# STM32U545xx register map
File version: 1.0
Registers are 32-bit, read-write, reset 0x0 unless marked. A register's access mark holds for its fields unless they carry their own. Offsets are from the block's base; [hi:lo] are bit positions; {n}, {i} and the like mark numbered series; 'fields as' and 'values as' point back to an identical list.

## VREFBUF
Base 0x46007400
Same registers: VREFBUF_S 0x56007400
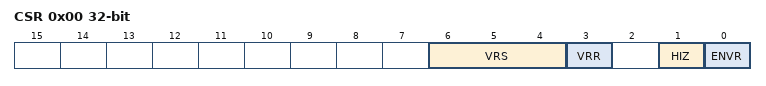
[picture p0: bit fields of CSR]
0x00 CSR — VREFBUF control and status register
  [6:4] VRS — Voltage reference scale
    {v}=SCALE{v} (Voltage reference scale {v} (VREF_OUT{v+1})) (v=0..3)
  [3] VRR — Voltage reference buffer ready
  [1] HIZ — High impedance mode
  [0] ENVR — Voltage reference buffer enable
0x04 CCR — VREFBUF calibration and control register
  [5:0] TRIM — TRIM[5:0] bits (Trimming code)

## EXTI — Asynch Interrupt/Event Controller (EXTI)
Base 0x46022000
Same registers: EXTI_S 0x56022000
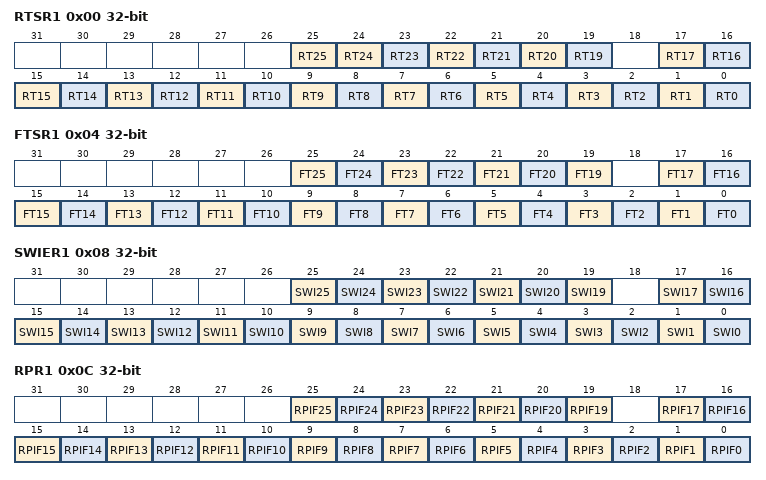
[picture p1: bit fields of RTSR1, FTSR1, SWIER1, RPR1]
0x00 RTSR1 — EXTI Rising Trigger Selection Register 1
  [25] RT25 — Rising trigger configuration for input line 24
  [n] RT{n} (n=19..24) — Rising trigger configuration for input line {n}
  [n] RT{n} (n=0..17) — Rising trigger configuration for input line {n}
0x04 FTSR1 — EXTI Falling Trigger Selection Register 1
  [n] FT{n} (n=19..25) — Falling trigger configuration for input line {n}
  [n] FT{n} (n=0..17) — Falling trigger configuration for input line {n}
0x08 SWIER1 — EXTI Software Interrupt event Register 1
  [n] SWI{n} (n=19..25) — Software Interrupt on line {n}
  [n] SWI{n} (n=0..17) — Software Interrupt on line {n}
0x0C RPR1 — EXTI Rising Pending Register 1
  [n] RPIF{n} (n=19..25) — Rising Pending Interrupt Flag on line {n}
  [n] RPIF{n} (n=0..17) — Rising Pending Interrupt Flag on line {n}
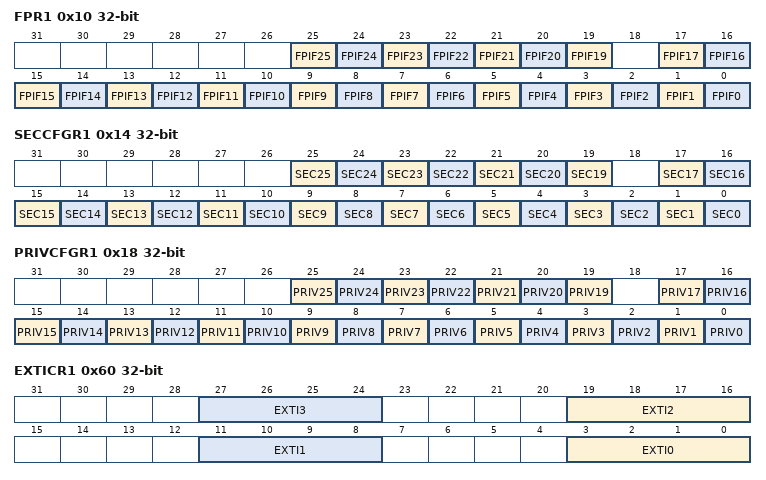
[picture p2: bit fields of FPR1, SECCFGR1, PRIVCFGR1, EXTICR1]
0x10 FPR1 — EXTI Falling Pending Register 1
  [n] FPIF{n} (n=19..25) — Falling Pending Interrupt Flag on line {n}
  [n] FPIF{n} (n=0..17) — Falling Pending Interrupt Flag on line {n}
0x14 SECCFGR1 — EXTI Security Configuration Register 1
  [n] SEC{n} (n=19..25) — Security enable on line {n}
  [n] SEC{n} (n=0..17) — Security enable on line {n}
0x18 PRIVCFGR1 — EXTI Privilege Configuration Register 1
  [n] PRIV{n} (n=19..25) — Privilege enable on line {n}
  [n] PRIV{n} (n=0..17) — Privilege enable on line {n}
0x60 EXTICR1 — EXIT External Interrupt Configuration Register, 0x60 -- 0x6C
  [8n+3:8n] EXTI{n} (n=0..3) — EXTI {n} configuration
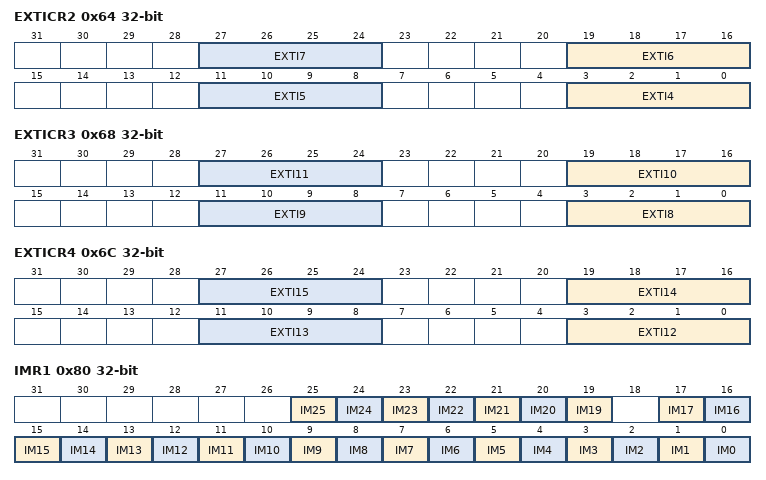
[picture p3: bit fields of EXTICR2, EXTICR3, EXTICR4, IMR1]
0x64 EXTICR2 — EXIT External Interrupt Configuration Register, 0x60 -- 0x6C
  [8n-29:8n-32] EXTI{n} (n=4..7) — EXTI {n} configuration
0x68 EXTICR3 — EXIT External Interrupt Configuration Register, 0x60 -- 0x6C
  [8n-61:8n-64] EXTI{n} (n=8..11) — EXTI {n} configuration
0x6C EXTICR4 — EXIT External Interrupt Configuration Register, 0x60 -- 0x6C
  [8n-93:8n-96] EXTI{n} (n=12..15) — EXTI {n} configuration
0x70 LOCKR — EXTI Lock Register
  [0] LOCK — Global security and privilege configuration registers lock
0x80 IMR1 — EXTI Interrupt Mask Register 1
  [n] IM{n} (n=19..25) — Interrupt Mask on line {n}
  [n] IM{n} (n=0..17) — Interrupt Mask on line {n}
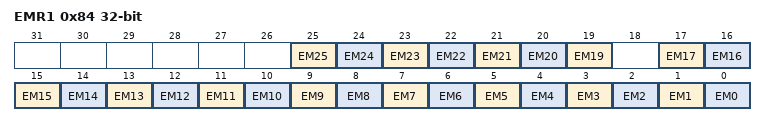
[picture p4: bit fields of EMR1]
0x84 EMR1 — EXTI Event Mask Register 1
  [n] EM{n} (n=19..25) — Event Mask on line {n}
  [n] EM{n} (n=0..17) — Event Mask on line {n}

## GTZC_TZIC2
Base 0x46023400
Same registers: GTZC_TZIC2_S 0x56023400
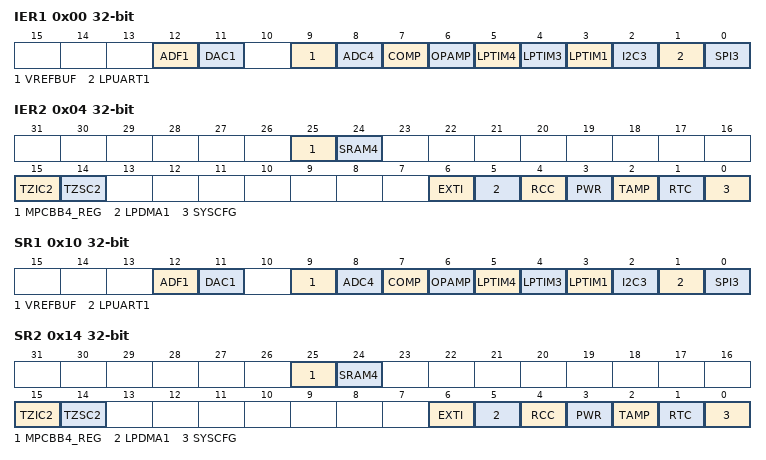
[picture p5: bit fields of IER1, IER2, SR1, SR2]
0x00 IER1 — TZIC interrupt enable register 1
  [12] ADF1, [11] DAC1, [9] VREFBUF, [8] ADC4, [7] COMP, [6] OPAMP, [5] LPTIM4, [4] LPTIM3, [3] LPTIM1, [2] I2C3, [1] LPUART1, [0] SPI3
0x04 IER2 — TZIC interrupt enable register 2
  [25] MPCBB4_REG, [24] SRAM4, [15] TZIC2, [14] TZSC2, [6] EXTI, [5] LPDMA1, [4] RCC, [3] PWR, [2] TAMP, [1] RTC, [0] SYSCFG
0x08 IER3 — TZIC interrupt enable register 3
0x0C IER4 — TZIC interrupt enable register 4
0x10 SR1 — TZIC status register 1
  fields as IER1
0x14 SR2 — TZIC status register 2
  fields as IER2
0x18 SR3 — TZIC status register 3
0x1C SR4 — TZIC status register 4
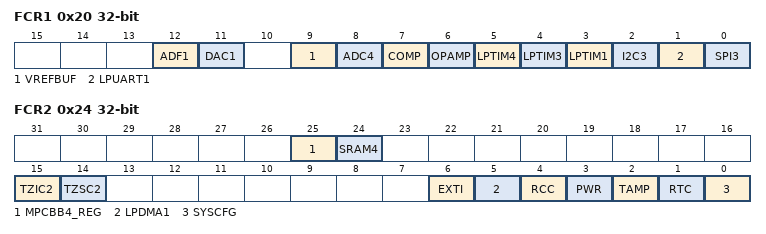
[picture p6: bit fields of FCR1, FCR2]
0x20 FCR1 — TZIC flag clear register 1
  fields as IER1
0x24 FCR2 — TZIC flag clear register 2
  fields as IER2
0x28 FCR3 — TZIC flag clear register 3
0x2C FCR4 — TZIC flag clear register 3

## DBGMCU — Debug MCU
Base 0xE0044000
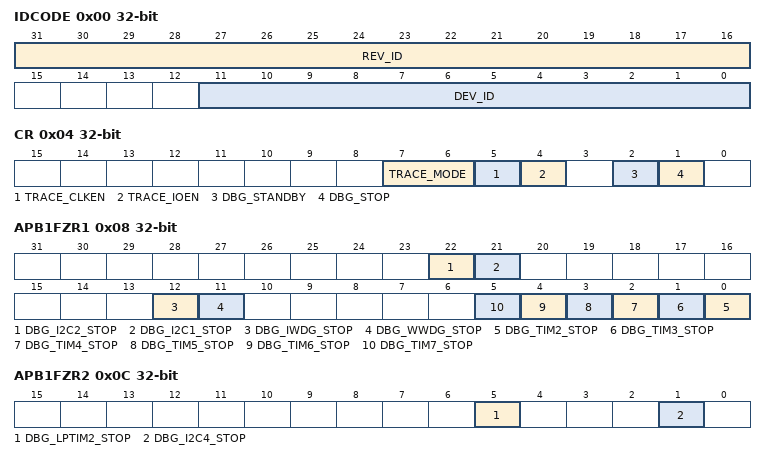
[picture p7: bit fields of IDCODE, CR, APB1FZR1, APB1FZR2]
0x00 IDCODE — MCU device ID code
  [31:16] REV_ID, [11:0] DEV_ID
0x04 CR — Debug MCU configuration register
  [7:6] TRACE_MODE, [5] TRACE_CLKEN, [4] TRACE_IOEN, [2] DBG_STANDBY, [1] DBG_STOP
0x08 APB1FZR1 — Debug MCU APB1 freeze register 1
  [22] DBG_I2C2_STOP, [21] DBG_I2C1_STOP, [12] DBG_IWDG_STOP, [11] DBG_WWDG_STOP, [n-2] DBG_TIM{n}_STOP (n=2..7)
0x0C APB1FZR2 — Debug MCU APB1 freeze register 2
  [5] DBG_LPTIM2_STOP, [1] DBG_I2C4_STOP
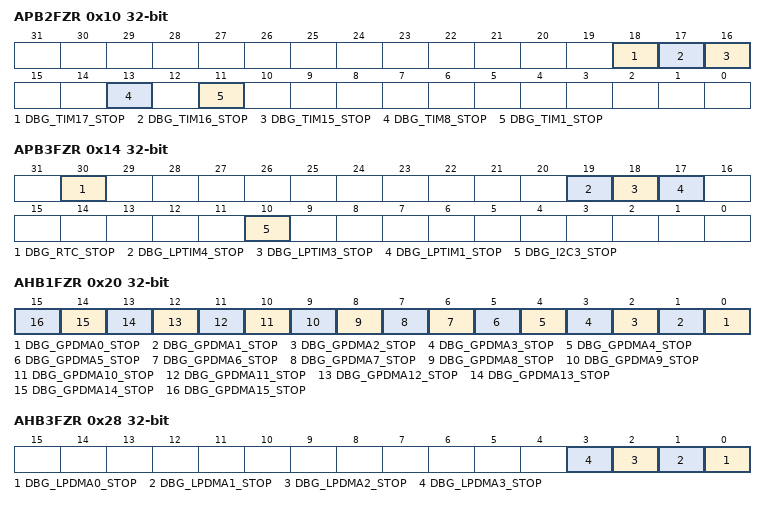
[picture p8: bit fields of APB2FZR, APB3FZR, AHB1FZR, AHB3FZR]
0x10 APB2FZR — Debug MCU APB2 freeze register
  [18] DBG_TIM17_STOP, [17] DBG_TIM16_STOP, [16] DBG_TIM15_STOP, [13] DBG_TIM8_STOP, [11] DBG_TIM1_STOP
0x14 APB3FZR — Debug MCU APB3 freeze register
  [30] DBG_RTC_STOP, [19] DBG_LPTIM4_STOP, [18] DBG_LPTIM3_STOP, [17] DBG_LPTIM1_STOP, [10] DBG_I2C3_STOP
0x20 AHB1FZR — Debug MCU AHB1 freeze register
  [n] DBG_GPDMA{n}_STOP (n=0..15)
0x28 AHB3FZR — Debug MCU AHB3 freeze register
  [n] DBG_LPDMA{n}_STOP (n=0..3)
